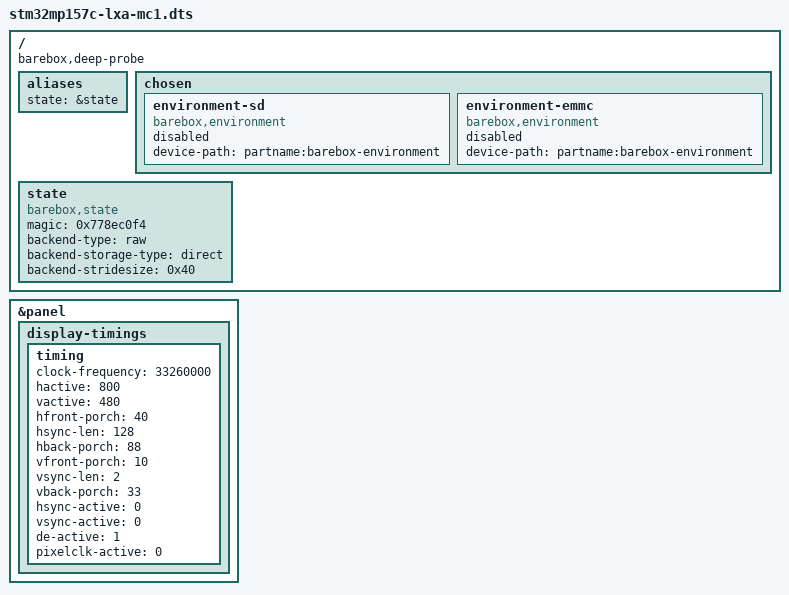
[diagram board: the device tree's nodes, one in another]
// SPDX-License-Identifier: (GPL-2.0+ OR BSD-3-Clause)
/*
 * Copyright (C) 2020 Ahmad Fatoum, Pengutronix
 */

#include <arm/st/stm32mp157c-lxa-mc1.dts>
#include "stm32mp151.dtsi"

/ {
	barebox,deep-probe;

	aliases {
		state = &state;
	};

	chosen {
		environment-sd {
			compatible = "barebox,environment";
			device-path = &sdmmc1, "partname:barebox-environment";
			status = "disabled";
		};

		environment-emmc {
			compatible = "barebox,environment";
			device-path = &sdmmc2, "partname:barebox-environment";
			status = "disabled";
		};
	};

	state: state {
		compatible = "barebox,state";
		magic = <0x778ec0f4>;
		/* backend is fixed up by board code */
		backend-type = "raw";
		backend-storage-type = "direct";
		backend-stridesize = <0x40>;

		#include "bootstate.dtsi"
	};
};

&panel {
	display-timings {
		timing { /* edt,etm0700g0dh6 */
			clock-frequency = <33260000>;
			hactive = <800>;
			vactive = <480>;
			hfront-porch = <40>;
			hsync-len = <128>;
			hback-porch = <88>;
			vfront-porch = <10>;
			vsync-len = <2>;
			vback-porch = <33>;
			hsync-active = <0>;
			vsync-active = <0>;
			de-active = <1>;
			pixelclk-active = <0>;
		};
	};
};
